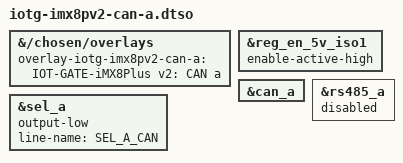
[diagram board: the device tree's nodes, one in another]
#include "overlay.h"

&{/chosen/overlays} {
	overlay-iotg-imx8pv2-can-a = "IOT-GATE-iMX8Plus v2: CAN a";
};

/* Enable ISO1_5V */
&reg_en_5v_iso1 {
	enable-active-high;
};

/* Enable CAN A interface */
&can_a {
	status = "okay";
};

/* Disable RS485 A interface */
&rs485_a {
	status = "disabled";
};

/* Select CAN signals on the MUX-A */
&sel_a {
	output-low;
	line-name = "SEL_A_CAN";
	status = "okay";
};
